# UPD70F3508 register map
Vendor: Renesas; Series: V850E2/Px4; File version: 1.0
CPU: other r0p0, little endian, no MPU, FPU, 4 interrupt priority bits
Registers are 8-bit, read-write, reset 0x0 unless marked. A register's access mark holds for its fields unless they carry their own. Offsets are from the block's base; [hi:lo] are bit positions.

## TPBA1 — Timer Pulse Buffer Array 1 — 16-bit PWM timer with duty setting buffer (instance 1)
Base 0xFF833000
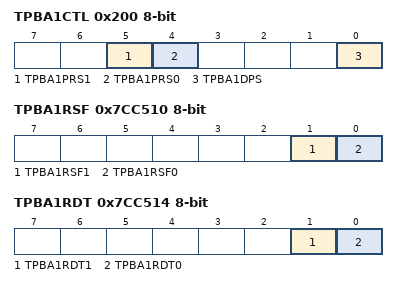
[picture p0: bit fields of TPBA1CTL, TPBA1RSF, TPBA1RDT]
0x200 TPBA1CTL — TPBA1 Control Register — selects count clock prescaler and duty pattern mode
  [5] TPBA1PRS1 — Count clock prescaler select bit 1 (with PRS0: 00=PCLK, 01=PCLK/2, 10=PCLK/4, 11=PCLK/8)
  [4] TPBA1PRS0 — Count clock prescaler select bit 0
  [0] TPBA1DPS — Duty setting pattern mode: 0=16-bit 64-patterns, 1=8-bit 128-patterns
0x7CC400 TPBA1BUF00 16-bit — TPBA1 Duty Setting Register 00 (representative; BUF01..BUF63 at base1+0x004*m, m=0..63). Sets duty value for pattern 1 (16-bit mode) or patterns 1-2 (8-bit mode).
  [15:0] TPBA1BUF00 — Duty value bits [15:0]
0x7CC500 TPBA1CMP0 16-bit — TPBA1 Period Setting Register — 16-bit compare register; PWM period = (CMP0+1) × count clock
  [15:0] TPBA1CMP0 — Period compare value [15:0]
0x7CC504 TPBA1CMP1 — TPBA1 Pattern Number Setting Register — sets number of PWM output patterns [6:0]
  [6:0] TPBA1CMP1 — Number of patterns [6:0] (0-63 in 16-bit mode, 0-127 in 8-bit mode)
0x7CC508 TPBA1CNT0 16-bit ro reset 0xFFFF — TPBA1 Timer Counter Register — 16-bit counter current value (read-only)
  [15:0] TPBA1CNT0 — 16-bit counter value [15:0]
0x7CC50C TPBA1CNT1 ro — TPBA1 Address Counter Register — 7-bit counter indicating address pointer to duty setting register
  [6:0] TPBA1CNT1 — 7-bit address counter value [6:0]
0x7CC510 TPBA1RSF ro — TPBA1 Reload Status Register — indicates pending reload requests
  [1] TPBA1RSF1 — Reload request flag for CMP1: 0=none/complete, 1=reload request pending
  [0] TPBA1RSF0 — Reload request flag for CMP0 and TOL: 0=none/complete, 1=reload request pending
0x7CC514 TPBA1RDT wo — TPBA1 Reload Data Trigger Register — enables reload of compare/output-level registers (always read as 0)
  [1] TPBA1RDT1 — Reload enable for CMP1: writing 1 enables reload (sets RSF1); 0 is ignored
  [0] TPBA1RDT0 — Reload enable for CMP0 and TOL: writing 1 enables reload (sets RSF0); 0 is ignored
0x7CC518 TPBA1RDM — TPBA1 Reload Data Mode Register — controls reload timing of CMP0 and TOL
  [0] TPBA1RDM0 — Reload timing: 0=synchronous with INTTPBAnIPAT, 1=synchronous with INTTPBAnIPRD
0x7CC51C TPBA1TO — TPBA1 Timer Output Register — reads/sets TPBnO pin output level
  [0] TPBA1TO0 — Output level: 0=low, 1=high (write ignored when timer output enabled)
0x7CC520 TPBA1TOE — TPBA1 Timer Output Enable Register — enables/disables PWM output from TPBnO pin
  [0] TPBA1TOE0 — Timer output enable: 0=output disabled (software control via TO), 1=PWM output enabled
0x7CC524 TPBA1TOL — TPBA1 Timer Output Level Register — specifies active level of PWM output (reload register)
  [0] TPBA1TOL0 — Active output level: 0=high active, 1=low active
0x7CC528 TPBA1TE ro — TPBA1 Enable Status Register — indicates whether timer counter is running
  [0] TPBA1TE0 — Timer enable status: 0=stopped, 1=operating
0x7CC52C TPBA1TS wo — TPBA1 Start Trigger Register — writing 1 starts the timer counter (always read as 0)
  [0] TPBA1TS0 — Start trigger: 0=ignored, 1=starts counting (TE0 set to 1)
0x7CC530 TPBA1TT wo — TPBA1 Stop Trigger Register — writing 1 stops the timer counter (always read as 0)
  [0] TPBA1TT0 — Stop trigger: 0=ignored, 1=stops counting (TE0 cleared to 0)

## DCRA0_CTL — Data CRC Function A, instance 0 — CTL register (base1 = 0xFF836000)
Base 0xFF836020
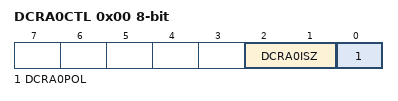
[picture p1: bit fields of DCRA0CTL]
0x00 DCRA0CTL — CRC Control Register — instance 0; selects polynomial and input bit width
  [2:1] DCRA0ISZ — CRC input bit width: 00=32-bit, 01=16-bit, 10=8-bit, 11=prohibited
  [0] DCRA0POL — CRC polynomial select: 0=32-bit Ethernet (04C11DB7H) LSB-first, 1=16-bit CCITT (1021H) MSB-first
